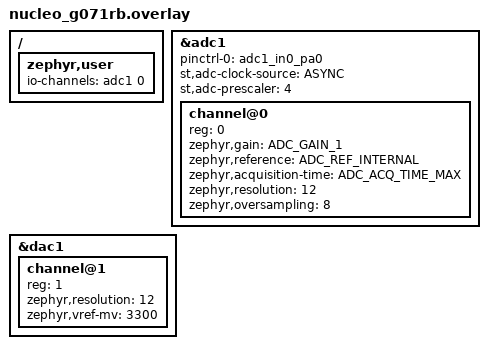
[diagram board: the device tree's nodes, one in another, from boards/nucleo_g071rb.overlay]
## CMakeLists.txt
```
#
# SPDX-License-Identifier: Apache-2.0
#

cmake_minimum_required(VERSION 3.20.0)

find_package(Zephyr REQUIRED HINTS $ENV{ZEPHYR_BASE})
project(nucleo_g071rb_adc_1ch)

target_sources(app PRIVATE src/main.c)
```

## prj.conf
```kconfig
CONFIG_ADC=y
CONFIG_DAC=y
```

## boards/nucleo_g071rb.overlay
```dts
/*
 * SPDX-License-Identifier: Apache-2.0
 *
 * NUCLEO-G071RB Arduino A0 = PA0 = ADC1_IN0.
 * DAC1_OUT1 = PA4 = Arduino A2.
 */

#include <zephyr/dt-bindings/adc/adc.h>

/ {
	zephyr,user {
		io-channels = <&adc1 0>;
	};
};

&adc1 {
	pinctrl-0 = <&adc1_in0_pa0>;
	pinctrl-names = "default";
	st,adc-clock-source = "ASYNC";
	st,adc-prescaler = <4>;
	status = "okay";

	#address-cells = <1>;
	#size-cells = <0>;

	channel@0 {
		reg = <0>;
		zephyr,gain = "ADC_GAIN_1";
		zephyr,reference = "ADC_REF_INTERNAL";
		zephyr,acquisition-time = <ADC_ACQ_TIME_MAX>;
		zephyr,resolution = <12>;
		zephyr,oversampling = <8>;
	};
};

&dac1 {
	status = "okay";

	#address-cells = <1>;
	#size-cells = <0>;

	channel@1 {
		reg = <1>;
		zephyr,resolution = <12>;
		zephyr,vref-mv = <3300>;
	};
};
```

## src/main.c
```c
/*
 * SPDX-License-Identifier: Apache-2.0
 */

#include <errno.h>
#include <inttypes.h>
#include <stdint.h>

#include <zephyr/devicetree.h>
#include <zephyr/drivers/adc.h>
#include <zephyr/drivers/dac.h>
#include <zephyr/kernel.h>
#include <zephyr/sys/printk.h>

#include <stm32_ll_adc.h>

#define ADC_NODE DT_PATH(zephyr_user)
#define ADC_READ_INTERVAL_MS 1000
#define STM32_ADC_CHANNEL_ID DT_IO_CHANNELS_INPUT_BY_IDX(ADC_NODE, 0)
#define STM32_ADC_LL_CHANNEL __LL_ADC_DECIMAL_NB_TO_CHANNEL(STM32_ADC_CHANNEL_ID)
#define STM32_ADC_RESOLUTION 12U
#define STM32_ADC_RAW_MAX ((1U << STM32_ADC_RESOLUTION) - 1U)
#define STM32_ADC_OVERSAMPLING_RATIO 256U
#define STM32_ADC_OVERSAMPLING_SHIFT 4U
#define STM32_ADC_OVERSAMPLING_DIVISOR (1U << STM32_ADC_OVERSAMPLING_SHIFT)
#define STM32_ADC_READY_TIMEOUT_US 10000U
#define DAC_NODE DT_NODELABEL(dac1)
#define DAC_CHANNEL_ID 1U
#define DAC_RESOLUTION 12U
#define DAC_OUTPUT_MV 3U
#define DAC_VREF_MV 3300U
#define DAC_RAW_MAX ((1U << DAC_RESOLUTION) - 1U)

#if !DT_NODE_EXISTS(ADC_NODE) || !DT_NODE_HAS_PROP(ADC_NODE, io_channels)
#error "No ADC channel configured in /zephyr,user io-channels"
#endif

static const struct adc_dt_spec adc_channel =
	ADC_DT_SPEC_GET_BY_IDX(ADC_NODE, 0);

static const struct dac_channel_cfg dac_channel_cfg = {
	.channel_id = DAC_CHANNEL_ID,
	.resolution = DAC_RESOLUTION,
	.buffered = false,
};

static const struct device *const dac_dev = DEVICE_DT_GET(DAC_NODE);

static int dac_set_test_voltage(uint32_t output_mv, uint32_t *raw)
{
	int err;
	uint32_t value;

	if (!device_is_ready(dac_dev)) {
		printk("DAC controller %s is not ready\n", dac_dev->name);
		return -ENODEV;
	}

	err = dac_channel_setup(dac_dev, &dac_channel_cfg);
	if (err < 0) {
		printk("Could not setup DAC channel %u (%d)\n",
		       DAC_CHANNEL_ID, err);
		return err;
	}

	value = ((output_mv * DAC_RAW_MAX) + (DAC_VREF_MV / 2U)) / DAC_VREF_MV;

	err = dac_write_value(dac_dev, DAC_CHANNEL_ID, value);
	if (err < 0) {
		printk("Could not write DAC channel %u (%d)\n",
		       DAC_CHANNEL_ID, err);
		return err;
	}

	*raw = value;
	return 0;
}

static void dac_print_registers(void)
{
	printk("DAC registers: DHR12R1=%lu DOR1=%lu\n",
	       DAC1->DHR12R1, DAC1->DOR1);
}

static int stm32_ll_adc_disable_for_config(void)
{
	uint32_t timeout = STM32_ADC_READY_TIMEOUT_US;

	if (LL_ADC_REG_IsConversionOngoing(ADC1)) {
		LL_ADC_REG_StopConversion(ADC1);
		while (LL_ADC_REG_IsConversionOngoing(ADC1) ||
		       LL_ADC_REG_IsStopConversionOngoing(ADC1)) {
			if (--timeout == 0U) {
				return -ETIMEDOUT;
			}
			k_busy_wait(1);
		}
	}

	if (LL_ADC_IsEnabled(ADC1)) {
		timeout = STM32_ADC_READY_TIMEOUT_US;
		LL_ADC_Disable(ADC1);
		while (LL_ADC_IsEnabled(ADC1)) {
			if (--timeout == 0U) {
				return -ETIMEDOUT;
			}
			k_busy_wait(1);
		}
	}

	return 0;
}

static int stm32_ll_adc_enable(void)
{
	uint32_t timeout = STM32_ADC_READY_TIMEOUT_US;

	if (LL_ADC_IsEnabled(ADC1)) {
		return 0;
	}

	LL_ADC_ClearFlag_ADRDY(ADC1);
	LL_ADC_Enable(ADC1);
	while (!LL_ADC_IsActiveFlag_ADRDY(ADC1)) {
		if (--timeout == 0U) {
			return -ETIMEDOUT;
		}
		k_busy_wait(1);
	}

	return 0;
}

static int stm32_ll_adc_configure(void)
{
	int err;

	err = stm32_ll_adc_disable_for_config();
	if (err < 0) {
		return err;
	}

	LL_ADC_SetResolution(ADC1, LL_ADC_RESOLUTION_12B);
	LL_ADC_REG_SetTriggerSource(ADC1, LL_ADC_REG_TRIG_SOFTWARE);
	LL_ADC_REG_SetSequencerLength(ADC1, LL_ADC_REG_SEQ_SCAN_DISABLE);
	LL_ADC_REG_SetSequencerRanks(ADC1, LL_ADC_REG_RANK_1,
				     STM32_ADC_LL_CHANNEL);
	LL_ADC_SetOverSamplingScope(ADC1, LL_ADC_OVS_GRP_REGULAR_CONTINUED);
	LL_ADC_ConfigOverSamplingRatioShift(ADC1, LL_ADC_OVS_RATIO_256,
					    LL_ADC_OVS_SHIFT_RIGHT_4);

	return stm32_ll_adc_enable();
}

static int stm32_ll_adc_read_raw16(uint16_t *raw_16)
{
	uint32_t timeout = STM32_ADC_READY_TIMEOUT_US;
	uint32_t value;

	LL_ADC_ClearFlag_EOC(ADC1);
	LL_ADC_ClearFlag_EOS(ADC1);
	LL_ADC_ClearFlag_OVR(ADC1);
	LL_ADC_REG_StartConversion(ADC1);

	while (!LL_ADC_IsActiveFlag_EOC(ADC1) && !LL_ADC_IsActiveFlag_EOS(ADC1)) {
		if (--timeout == 0U) {
			return -ETIMEDOUT;
		}
		k_busy_wait(1);
	}

	value = LL_ADC_REG_ReadConversionData32(ADC1);
	*raw_16 = (uint16_t)value;

	return 0;
}

static const char *stm32_ll_sampling_cycles(void)
{
	uint32_t sampling_time;

	sampling_time = LL_ADC_GetChannelSamplingTime(ADC1, STM32_ADC_LL_CHANNEL);

	switch (sampling_time) {
#ifdef LL_ADC_SAMPLINGTIME_1CYCLE_5
	case LL_ADC_SAMPLINGTIME_1CYCLE_5:
		return "1.5";
#endif
#ifdef LL_ADC_SAMPLINGTIME_2CYCLES_5
	case LL_ADC_SAMPLINGTIME_2CYCLES_5:
		return "2.5";
#endif
#ifdef LL_ADC_SAMPLINGTIME_3CYCLES_5
	case LL_ADC_SAMPLINGTIME_3CYCLES_5:
		return "3.5";
#endif
#ifdef LL_ADC_SAMPLINGTIME_6CYCLES_5
	case LL_ADC_SAMPLINGTIME_6CYCLES_5:
		return "6.5";
#endif
#ifdef LL_ADC_SAMPLINGTIME_7CYCLES_5
	case LL_ADC_SAMPLINGTIME_7CYCLES_5:
		return "7.5";
#endif
#ifdef LL_ADC_SAMPLINGTIME_12CYCLES_5
	case LL_ADC_SAMPLINGTIME_12CYCLES_5:
		return "12.5";
#endif
#ifdef LL_ADC_SAMPLINGTIME_19CYCLES_5
	case LL_ADC_SAMPLINGTIME_19CYCLES_5:
		return "19.5";
#endif
#ifdef LL_ADC_SAMPLINGTIME_39CYCLES_5
	case LL_ADC_SAMPLINGTIME_39CYCLES_5:
		return "39.5";
#endif
#ifdef LL_ADC_SAMPLINGTIME_79CYCLES_5
	case LL_ADC_SAMPLINGTIME_79CYCLES_5:
		return "79.5";
#endif
#ifdef LL_ADC_SAMPLINGTIME_160CYCLES_5
	case LL_ADC_SAMPLINGTIME_160CYCLES_5:
		return "160.5";
#endif
	default:
		return "unknown";
	}
}

static uint32_t stm32_ll_oversampling_ratio(void)
{
	switch (LL_ADC_GetOverSamplingRatio(ADC1)) {
	case LL_ADC_OVS_RATIO_256:
		return 256U;
	default:
		return 0U;
	}
}

static uint32_t stm32_ll_oversampling_shift(void)
{
	switch (LL_ADC_GetOverSamplingShift(ADC1)) {
	case LL_ADC_OVS_SHIFT_RIGHT_4:
		return 4U;
	default:
		return 0U;
	}
}

static uint16_t stm32_ll_adc_raw16_to_raw12(uint16_t raw_16)
{
	uint32_t raw_12;

	raw_12 = ((uint32_t)raw_16 + (STM32_ADC_OVERSAMPLING_DIVISOR / 2U)) /
		 STM32_ADC_OVERSAMPLING_DIVISOR;

	if (raw_12 > STM32_ADC_RAW_MAX) {
		return STM32_ADC_RAW_MAX;
	}

	return (uint16_t)raw_12;
}

static int stm32_ll_adc_raw16_to_centi_millivolts(uint16_t raw_16,
						  int32_t *centi_mv)
{
	int64_t value;
	int32_t vref_mv;
	uint32_t resolution_scale;
	int ret;

	if (!adc_channel.channel_cfg_dt_node_exists) {
		return -ENOTSUP;
	}

	if (adc_channel.channel_cfg.reference == ADC_REF_INTERNAL) {
		vref_mv = adc_ref_internal(adc_channel.dev);
	} else {
		vref_mv = adc_channel.vref_mv;
	}

	if (vref_mv == 0) {
		return -ENOTSUP;
	}

	value = (int64_t)raw_16 * vref_mv * 100;
	ret = adc_gain_invert_64(adc_channel.channel_cfg.gain, &value);
	if (ret < 0) {
		return ret;
	}

	resolution_scale = 1U << (STM32_ADC_RESOLUTION +
				  STM32_ADC_OVERSAMPLING_SHIFT);
	value = (value + (resolution_scale / 2U)) / resolution_scale;

	*centi_mv = (int32_t)value;
	return 0;
}

static void stm32_ll_print_calibration(void)
{
	printk("STM32 LL ADC calibration: factor=%lu CALFACT=0x%08lx\n",
	       LL_ADC_GetCalibrationFactor(ADC1), ADC1->CALFACT);
}

int main(void)
{
	int err;
	uint32_t count = 0;
	uint32_t dac_raw;

	if (!adc_is_ready_dt(&adc_channel)) {
		printk("ADC controller %s is not ready\n", adc_channel.dev->name);
		return 0;
	}

	err = dac_set_test_voltage(DAC_OUTPUT_MV, &dac_raw);
	if (err < 0) {
		return 0;
	}

	err = adc_channel_setup_dt(&adc_channel);
	if (err < 0) {
		printk("Could not setup ADC channel %d (%d)\n",
		       adc_channel.channel_id, err);
		return 0;
	}

	err = stm32_ll_adc_configure();
	if (err < 0) {
		printk("Could not configure ADC with STM32 LL (%d)\n", err);
		return 0;
	}

	printk("NUCLEO-G071RB ADC sample started: %s channel %d\n",
	       adc_channel.dev->name, adc_channel.channel_id);
	printk("DAC test output: %s channel=%u raw=%u target=%u mV "
	       "pin=PA4/Arduino A2, jumper A2 to A0\n",
	       dac_dev->name, DAC_CHANNEL_ID, dac_raw, DAC_OUTPUT_MV);
	dac_print_registers();
	printk("STM32 LL ADC config: channel=%u sampling=%s cycles "
	       "oversampling_ratio=%u shift=%u\n",
	       STM32_ADC_CHANNEL_ID, stm32_ll_sampling_cycles(),
	       stm32_ll_oversampling_ratio(), stm32_ll_oversampling_shift());
	stm32_ll_print_calibration();

	while (true) {
		uint16_t raw_12;
		uint16_t raw_16;
		int32_t val_centi_mv;

		err = stm32_ll_adc_read_raw16(&raw_16);
		if (err < 0) {
			printk("[%u] ADC read failed (%d)\n", count++, err);
			k_msleep(ADC_READ_INTERVAL_MS);
			continue;
		}

		raw_12 = stm32_ll_adc_raw16_to_raw12(raw_16);

		printk("[%u] ll_channel=%u sampling=%s cycles ovs_ratio=%u "
		       "shift=%u raw16=%u raw12=%u dac_dor1=%lu",
		       count++, STM32_ADC_CHANNEL_ID, stm32_ll_sampling_cycles(),
		       STM32_ADC_OVERSAMPLING_RATIO, STM32_ADC_OVERSAMPLING_SHIFT,
		       raw_16, raw_12, DAC1->DOR1);

		err = stm32_ll_adc_raw16_to_centi_millivolts(raw_16,
							     &val_centi_mv);
		if (err < 0) {
			printk(" mV=N/A\n");
		} else {
			printk(" voltage=%" PRId32 ".%02" PRId32 " mV\n",
			       val_centi_mv / 100, val_centi_mv % 100);
		}

		k_msleep(ADC_READ_INTERVAL_MS);
	}

	return 0;
}
```
